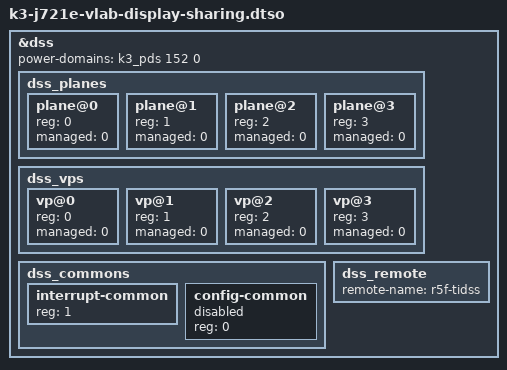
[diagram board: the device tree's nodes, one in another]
// SPDX-License-Identifier: GPL-2.0
/*
 * Device Tree Source for J721E ASTC VLAB Model with DSS partitioning support
 *
 * Copyright (C) 2016-2018 Texas Instruments Incorporated - http://www.ti.com/
 */

/dts-v1/;
/plugin/;

&dss {
	power-domains = <&k3_pds 152 0>;

	dss_planes: dss_planes {
		#address-cells = <1>;
		#size-cells = <0>;

		/*vid1*/
		plane@0 {
			reg = <0>;
			managed = <0>;
		};

		/*vidl1*/
		plane@1 {
			reg = <1>;
			managed = <0>;
		};

		/*vid2*/
		plane@2 {
			reg = <2>;
			managed = <0>;
		};

		/*vidl2*/
		plane@3 {
			reg = <3>;
			managed = <0>;
		};
	};

	dss_vps: dss_vps {
		#address-cells = <1>;
		#size-cells = <0>;

		vp@0 {
			reg = <0>;
			managed = <0>;
		};

		vp@1 {
			reg = <1>;
			managed = <0>;
		};

		vp@2 {
			reg = <2>;
			managed = <0>;
		};

		vp@3 {
			reg = <3>;
			managed = <0>;
		};
	};

	dss_commons: dss_commons {
		#address-cells = <1>;
		#size-cells = <0>;

		interrupt-common {
			reg = <1>;
		};

		config-common {
			status = "disabled";
			reg = <0>;
		};
	};

	dss_remote: dss_remote {
		#address-cells = <0>;
		#size-cells = <0>;

		remote-name = "r5f-tidss";
	};
};
